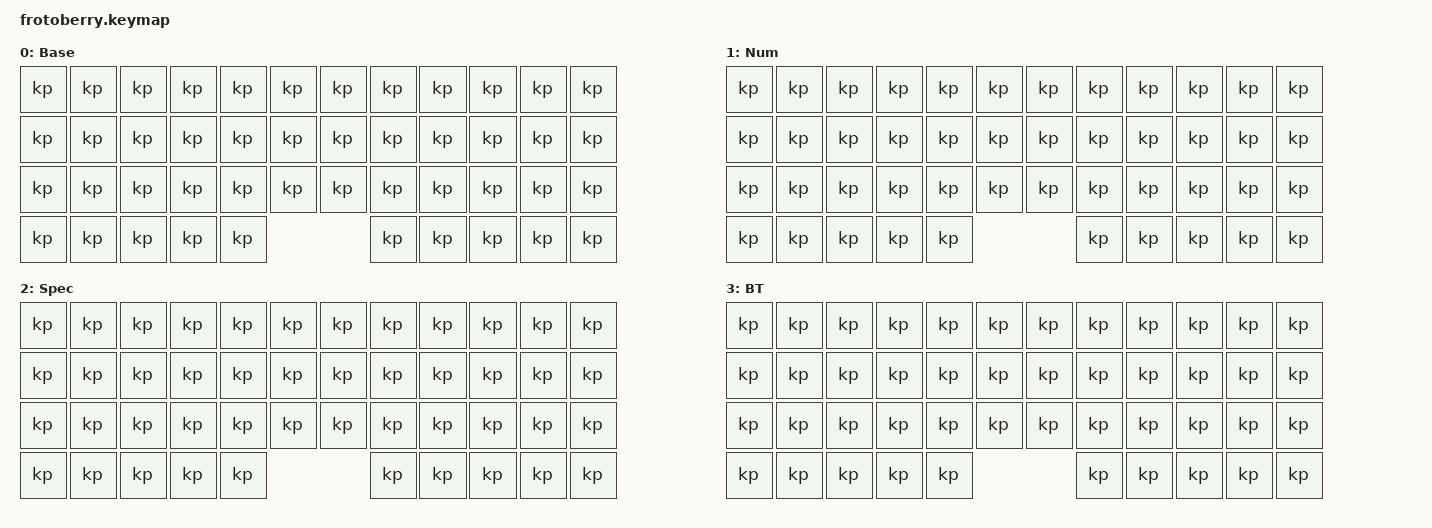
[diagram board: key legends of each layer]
#include <behaviors.dtsi>
#include <dt-bindings/zmk/keys.h>
#include <dt-bindings/zmk/bt.h>

/ {
    combos{ compatible = "zmk,combos"}; //Behöver jag detta??

    behaviors{
        
        // prevent multiple uppercase letters on sticky shift
        skq: sticky_key_quick_release {
            compatible = "zmk,behavior-sticky-key";
            label = "STICKY_KEY_QUICK_RELEASE";
            #binding-cells = <1>;
            bindings = <&kp>;
            release-after-ms = <1000>;
            quick-release;
            //ignore-modifiers;
        };

        // hold: shift | tap: quick sticky shift | dtap: caps-word
        Hodl: Hodl {
            compatible = "zmk,behavior-tap-dance";
            label = "HODL";
            #binding-cells = <0>;
            bindings = <&skq LSHIFT>, <&caps_word>;
        };
    };

    keymap {
        compatible = "zmk,keymap";

        layer_0 { //layer 0
            display-name = "Base";
            bindings = <
                &kp &kp &kp &kp &kp &kp &kp &kp &kp &kp &kp &kp
                &kp &kp &kp &kp &kp &kp &kp &kp &kp &kp &kp &kp
                &kp &kp &kp &kp &kp &kp &kp &kp &kp &kp &kp &kp
                &kp &kp &kp &kp   &kp     &kp   &kp &kp &kp &kp
            >;
        };

        layer_1 { //layer 0
            display-name = "Num";
            bindings = <
                &kp &kp &kp &kp &kp &kp &kp &kp &kp &kp &kp &kp
                &kp &kp &kp &kp &kp &kp &kp &kp &kp &kp &kp &kp
                &kp &kp &kp &kp &kp &kp &kp &kp &kp &kp &kp &kp
                &kp &kp &kp &kp   &kp     &kp   &kp &kp &kp &kp
            >;
        };

        layer_2 { //layer 0
            display-name = "Spec";
            bindings = <
                &kp &kp &kp &kp &kp &kp &kp &kp &kp &kp &kp &kp
                &kp &kp &kp &kp &kp &kp &kp &kp &kp &kp &kp &kp
                &kp &kp &kp &kp &kp &kp &kp &kp &kp &kp &kp &kp
                &kp &kp &kp &kp   &kp     &kp   &kp &kp &kp &kp
            >;
        };

        layer_bt { //layer 
            display-name = "BT";
            bindings = <
                &kp &kp &kp &kp &kp &kp &kp &kp &kp &kp &kp &kp
                &kp &kp &kp &kp &kp &kp &kp &kp &kp &kp &kp &kp
                &kp &kp &kp &kp &kp &kp &kp &kp &kp &kp &kp &kp
                &kp &kp &kp &kp   &kp     &kp   &kp &kp &kp &kp
            >;
        };
    };
};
